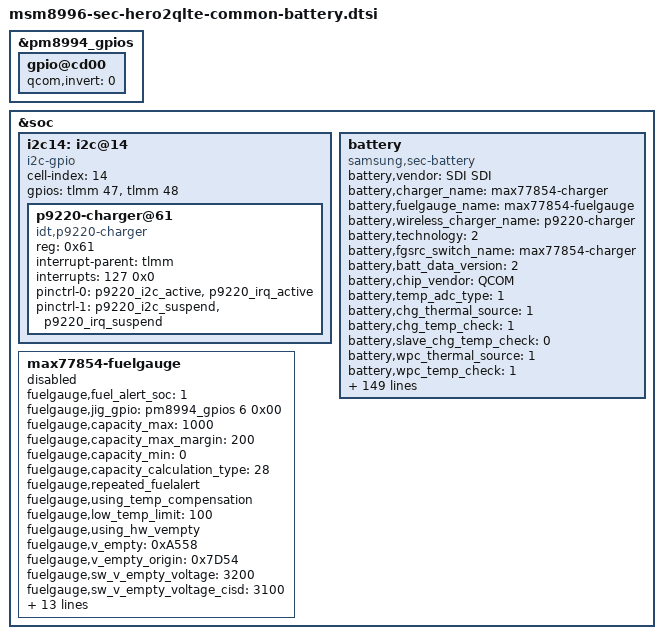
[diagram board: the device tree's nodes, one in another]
/* Copyright (c) 2014, The Linux Foundation. All rights reserved.
 *
 * This program is free software; you can redistribute it and/or modify
 * it under the terms of the GNU General Public License version 2 and
 * only version 2 as published by the Free Software Foundation.
 *
 * This program is distributed in the hope that it will be useful,
 * but WITHOUT ANY WARRANTY; without even the implied warranty of
 * MERCHANTABILITY or FITNESS FOR A PARTICULAR PURPOSE.  See the
 * GNU General Public License for more details.
 */

&pm8994_gpios {
	gpio@cd00 { /* GPIO 14 */
		qcom,invert = <0>;		/* Output low initially */
	};
};

&soc {
	i2c14: i2c@14 {
		cell-index = <14>;
		compatible = "i2c-gpio";
		gpios = <&tlmm 47 0 /* sda */
			&tlmm 48 0 /* scl */
			>;
		#address-cells = <1>;
		#size-cells = <0>;

		p9220-charger@61 {
			compatible = "idt,p9220-charger";
			reg = <0x61>;
			interrupt-parent = <&tlmm>;
			interrupts = <127 0x0>;
			pinctrl-names = "p9220_active", "p9220_suspend";
			pinctrl-0 = <&p9220_i2c_active &p9220_irq_active>;
			pinctrl-1 = <&p9220_i2c_suspend &p9220_irq_suspend>;
		};
	};

	battery {
		status = "okay";
		compatible = "samsung,sec-battery";
		battery,vendor = "SDI SDI";
		battery,charger_name = "max77854-charger";
		battery,fuelgauge_name = "max77854-fuelgauge";
		battery,wireless_charger_name = "p9220-charger";
		battery,technology = <2>; /* POWER_SUPPLY_TECHNOLOGY_LION */
		battery,fgsrc_switch_name = "max77854-charger"; /* Fuelgauge voltage source */

		battery,batt_data_version = <2>;

		battery,chip_vendor = "QCOM";
		battery,temp_adc_type = <1>; /* SEC_BATTERY_ADC_TYPE_AP */

		battery,chg_thermal_source = <1>;
		battery,chg_temp_check = <1>;
		battery,slave_chg_temp_check = <0>;
		battery,wpc_thermal_source = <1>;
		battery,wpc_temp_check = <1>;

		battery,polling_time = <10 30 30 30 3600>;

		battery,temp_table_adc = <25975 26200 26460 26722 27108 27455 27949 28525 29194 29950
					  30730 31610 32539 33689 34747 35834 36877 37894 38823 39662
					  40381 40983 41461>;
		battery,temp_table_data = <900 850 800 750 700 650 600 550 500 450
					   400 350 300 250 200 150 100 50 0 (-50)
					   (-100) (-150) (-200)>;

		battery,chg_temp_table_adc = <25877 26100 26362 26614 26989 27320 27821 28384 29043 29784
					  30549 31398 32316 33458 34511 35578 36599 37589 38441 39257
					  39980 40606 41070>;
		battery,chg_temp_table_data = <900 850 800 750 700 650 600 550 500 450
					   400 350 300 250 200 150 100 50 0 (-50)
					   (-100) (-150) (-200)>;

		battery,wpc_temp_table_adc = <25877 26100 26362 26614 26989 27320 27821 28384 29043 29784
					  30549 31398 32316 33458 34511 35578 36599 37589 38441 39257
					  39980 40606 41070>;
		battery,wpc_temp_table_data = <900 850 800 750 700 650 600 550 500 450
					   400 350 300 250 200 150 100 50 0 (-50)
					   (-100) (-150) (-200)>;

		battery,input_current_limit = <1800 500 500 1800 500 900 1000 500 1000 500 900 1900 1800 500 500 400 700 1300 300 1000 1500 500 1667 1000 1667 80 1800 1667 1400 1000 1000 500 660 900 600 900 900 660 1800 1667 1800>;
		battery,fast_charging_current = <2100 450 450 2100 700 1200 1000 500 1200 450 1440 1600 2100 450 450 400 700 1300 300 1000 1500 450 2600 1000 2600 80 1800 1000 1400 450 1000 500 1440 1440 1440 1440 1440 1440 2600 2600 2600>;
		battery,full_check_current_1st = <350 0 0 350 350 350 350 350 350 0 350 350 350 0 0 350 350 350 350 350 350 0 350 350 350 0 350 350 350 0 350 0 350 350 350 350 350 350 350 350 350>;
		battery,full_check_current_2nd = <200 0 0 200 200 200 200 200 200 0 200 200 200 0 0 200 200 200 200 200 200 0 200 200 200 0 200 200 200 0 200 0 200 200 200 200 200 200 200 200 200>;

		battery,wireless_cc_cv = <85>;
		/* Hero2 5V */
		battery,fod_data = <204 12 150 30 130 57 130 57 157 8 157 9>;
		battery,fod_data_cv = <204 42 150 60 130 87 130 87 157 38 157 39>;
		/* Hero2 9V */
		battery,fod_hv_data = <204 12 150 30 160 57 150 57 157 8 157 9>;
		battery,fod_hv_data_cv = <204 42 150 60 160 87 150 87 157 38 157 39>;
		battery,wpc_cc_cv_vout = <5500>;
		battery,wpc_cv_call_vout = <5000>;
		battery,wpc_cc_call_vout = <5000>;
		battery,wpc_det = <&pm8994_gpios 14 0x1>;
		battery,wpc_en = <&pm8004_mpps 2 0>; /* WPC_EN */
		battery,wpc_int = <&tlmm 127 0x00>;
		battery,hv_vout_wa = <0x41>; /* WC vout 10.0V */

		battery,adc_check_count = <5>;

		battery,cable_check_type = <4>; /* SEC_BATTERY_CABLE_CHECK_PSY */
		battery,cable_source_type = <1>; /* SEC_BATTERY_CABLE_SOURCE_EXTERNAL */
		battery,polling_type = <1>; /* SEC_BATTERY_MONITOR_ALARM */
		battery,monitor_initial_count = <3>;

		battery,battery_check_type = <0>; /* SEC_BATTERY_CHECK_NONE */
		battery,check_count = <0>;
		battery,check_adc_max = <1440>;
		battery,check_adc_min = <0>;

		battery,ovp_uvlo_check_type = <3>; /* SEC_BATTERY_OVP_UVLO_CHGPOLLING */

		battery,thermal_source = <2>; /* SEC_BATTERY_THERMAL_SOURCE_ADC */

		battery,temp_check_type = <2>; /* SEC_BATTERY_TEMP_CHECK_TEMP */
		battery,temp_check_count = <1>;
		battery,temp_highlimit_threshold_event = <800>;
		battery,temp_highlimit_recovery_event = <750>;
		battery,temp_high_threshold_event = <500>;
		battery,temp_high_recovery_event = <450>;
		battery,temp_low_threshold_event = <0>;
		battery,temp_low_recovery_event = <50>;
		battery,temp_highlimit_threshold_normal = <800>;
		battery,temp_highlimit_recovery_normal = <750>;
		battery,temp_high_threshold_normal = <500>;
		battery,temp_high_recovery_normal = <450>;
		battery,temp_low_threshold_normal = <0>;
		battery,temp_low_recovery_normal = <50>;
		battery,temp_highlimit_threshold_lpm = <800>;
		battery,temp_highlimit_recovery_lpm = <750>;
		battery,temp_high_threshold_lpm = <500>;
		battery,temp_high_recovery_lpm = <450>;
		battery,temp_low_threshold_lpm = <0>;
		battery,temp_low_recovery_lpm = <50>;

		battery,wpc_high_threshold_normal = <450>;
		battery,wpc_high_recovery_normal = <400>;
		battery,wpc_low_threshold_normal = <0>;
		battery,wpc_low_recovery_normal = <50>;

		battery,full_check_type = <7>; /* SEC_BATTERY_FULLCHARGED_CHGPSY */
		battery,full_check_type_2nd = <7>; /* SEC_BATTERY_FULLCHARGED_CHGPSY */
		battery,full_check_count = <1>;
		battery,chg_gpio_full_check = <0>;
		battery,chg_polarity_full_check = <1>;

		battery,chg_high_temp_1st = <485>;
		battery,chg_high_temp_2nd = <485>;
		battery,chg_high_temp_recovery = <480>;
		battery,chg_charging_limit_current = <1033>;
		battery,chg_charging_limit_current_2nd = <1033>;

		/* hero2 vzw */
		battery,wpc_high_temp = <400>;
		battery,wpc_high_temp_recovery = <390>;
		battery,wpc_lcd_on_high_temp = <380>;
		battery,wpc_lcd_on_high_temp_rec = <300>;

		battery,wpc_charging_limit_current = <450>;
		battery,sleep_mode_limit_current = <500>;
		battery,wc_full_input_limit_current = <100>;
		battery,wc_cv_current = <820>;

		battery,mix_temp_check = <1>;
		battery,mix_high_tbat = <400>;
		battery,mix_high_tchg = <500>;
		battery,mix_high_tbat_recov = <370>;
		battery,mix_input_limit_current = <100>;
		battery,mix_high_tbat_hv = <420>;
		battery,mix_high_tchg_hv = <500>;
		battery,mix_high_tbat_recov_hv = <390>;
		battery,mix_input_limit_current_hv = <100>;

		/* SEC_BATTERY_FULL_CONDITION_SOC |
		   SEC_BATTERY_FULL_CONDITION_NOTIMEFULL |
		   SEC_BATTERY_FULL_CONDITION_VCELL */
		battery,full_condition_type = <13>;
		battery,full_condition_soc = <93>;
		battery,full_condition_vcell = <4250>;

		battery,recharge_check_count = <1>;
		battery,recharge_condition_type = <4>; /* SEC_BATTERY_RECHARGE_CONDITION_VCELL */
		battery,recharge_condition_soc = <98>;
		battery,recharge_condition_vcell = <4280>;

		battery,charging_total_time = <21600>;
		battery,recharging_total_time = <5400>;
		battery,charging_reset_time = <0>;
		qcom,sec-battery-vadc = <&pm8994_vadc>;

		battery,chg_float_voltage = <43500>;
		battery,chg_float_voltage_conv = <10>;

		battery,swelling_high_temp_block = <410>;
		battery,swelling_high_temp_recov = <390>;
		battery,swelling_low_temp_block_1st = <150>;
		battery,swelling_low_temp_recov_1st = <200>;
		battery,swelling_low_temp_block_2nd = <100>;
		battery,swelling_low_temp_recov_2nd = <150>;

		battery,swelling_low_temp_current = <1080>;	/* 0.3C */
		battery,swelling_low_temp_topoff = <200>;	/* 0.05C */
		battery,swelling_high_temp_current = <1620>;	/* 0.45C */
		battery,swelling_high_temp_topoff = <200>;	/* 0.05C */
		battery,swelling_wc_low_temp_current = <1080>;	/* 0.3C */
		battery,swelling_wc_high_temp_current = <1080>;	/* 0.3C */

		battery,swelling_drop_float_voltage = <41500>;
		battery,swelling_high_rechg_voltage = <4000>;
		battery,swelling_low_rechg_voltage = <4000>;

		battery,siop_event_check_type = <1>;
		battery,siop_call_cv_current = <330>;
		battery,siop_call_cc_current = <330>;

		battery,siop_input_limit_current = <1200>;
		battery,siop_charging_limit_current = <1000>;
		battery,siop_hv_input_limit_current = <700>;
		battery,siop_hv_charging_limit_current = <1000>;

		battery,siop_wireless_input_limit_current = <600>;
		battery,siop_wireless_charging_limit_current = <1000>;
		battery,siop_hv_wireless_input_limit_current = <600>;
		battery,siop_hv_wireless_charging_limit_current = <1000>;

		battery,ttf_hv_charge_current = <2500>;
		battery,ttf_hv_wireless_charge_current = <1300>;

		battery,standard_curr = <2600>;
		battery,expired_time = <10800>;
		battery,recharging_expired_time = <5400>;

		/* cycle, chg_float_voltage, recharge_condition_vcell, full_condition_vcell, full_condition_soc */
		battery,age_data = <0 43500 4280 4250 93
			200 43250 4255 4225 92
			250 43125 4242 4212 91
			300 42875 4217 4187 90
			1000 42375 4167 4137 89>;

		battery,enable_coil_temp = <1>;
	};

	max77854-fuelgauge {
		status = "disable";
		fuelgauge,fuel_alert_soc = <1>;
		fuelgauge,jig_gpio = <&pm8994_gpios 6 0x00>;
		fuelgauge,capacity_max = <1000>;
		fuelgauge,capacity_max_margin = <200>;
		fuelgauge,capacity_min = <0>;
		fuelgauge,capacity_calculation_type = <28>;
		fuelgauge,repeated_fuelalert;
		fuelgauge,using_temp_compensation;
		fuelgauge,low_temp_limit = <100>;
		fuelgauge,using_hw_vempty;
		fuelgauge,v_empty = <0xA558>; /* Empty: 3300mV, Recover: 3520mV */
		fuelgauge,v_empty_origin = <0x7D54>; /* Empty: 2500mV, Recover: 3360mV */
		fuelgauge,sw_v_empty_voltage = <3200>;
		fuelgauge,sw_v_empty_voltage_cisd = <3100>;
		fuelgauge,sw_v_empty_recover_voltage = <3480>;
		fuelgauge,qrtable20 = <0x0903>;
		fuelgauge,qrtable30 = <0x0901>;
		fuelgauge,fg_resistor = <1>;
		fuelgauge,rcomp0 = <0x90>;
		fuelgauge,rcomp_charging = <0x90>;
		fuelgauge,is_using_model_data;
		fuelgauge,type_str = "SDI";
		fuelgauge,capacity = <0x1B5A>;
		/*fuelgauge,auto_discharge_en;*/
		fuelgauge,discharge_temp_threshold = <600>;
		fuelgauge,discharge_volt_threshold = <4200>;
		fuelgauge,cv_data = <
			2488	829	1809
			2409	832	1796
			2327	837	1769
			2272	840	1743
			2182	846	1721
			2104	850	1690
			2038	854	1670
			1950	859	1640
			1904	861	1622
			1838	865	1594
			1797	867	1576
			1749	870	1560
			1703	873	1531
			1683	873	1525
			1667	875	1515
			1660	875	1512
			1653	876	1509
			1615	878	1502
			1580	880	1483
			1553	881	1463
			1544	882	1458
			1520	883	1451
			1477	886	1424
			1431	888	1409
			1396	891	1383
			1347	894	1361
			1299	896	1332
			1267	898	1315
			1231	902	1288
			1202	904	1263
			1148	906	1243
			1109	909	1213
			1067	911	1185
			1031	914	1156
			1013	915	1140
			975	917	1111
			961	919	1084
			921	921	1064
			892	923	1038
			887	923	1019
			863	925	1004
			833	927	976
			808	929	946
			787	930	918
			780	931	904
			764	932	895
			744	934	864
			730	935	846
			715	936	828
			693	937	800
			681	938	783
			666	940	752
			651	941	735
			640	942	712
			628	945	697
			622	946	679
			618	947	664
			600	950	646
			596	951	627
			589	953	614
			584	953	601
			576	956	572
			577	957	553
			562	958	535
			511	968	506
			505	969	487
			493	971	464
			492	972	435
			484	973	417
			480	975	398
			474	976	380
			470	977	364
			462	977	355
			456	978	336
			452	979	329
			446	981	303
			437	982	282
			429	984	255
			423	985	242
			422	986	229
			414	987	211
			411	988	199
			405	989	191
			397	990	171
			391	991	140
			387	992	126
			384	993	107
			372	995	84
			364	997	54
			356	998	26
			356	998	13
			0	1000	0
			>;
	};
};
